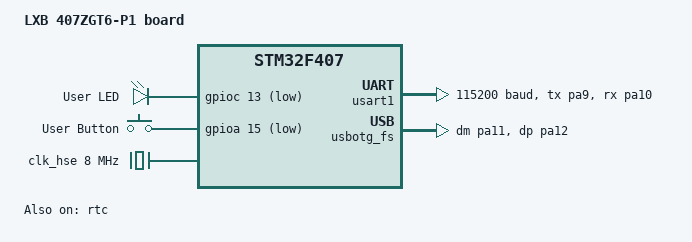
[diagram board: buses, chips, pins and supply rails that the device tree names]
/*
 * Copyright (c) 2026
 *
 * SPDX-License-Identifier: Apache-2.0
 *
 * Device tree for the LXB 407ZGT6-P1 core board (STM32F407ZGT6).
 */

/dts-v1/;
#include <st/f4/stm32f407Xg.dtsi>
#include <st/f4/stm32f407z(e-g)tx-pinctrl.dtsi>
#include <zephyr/dt-bindings/input/input-event-codes.h>

/ {
	model = "LXB 407ZGT6-P1 board";
	compatible = "st,stm32f407";

	chosen {
		zephyr,console = &usart1;
		zephyr,shell-uart = &usart1;
		zephyr,sram = &sram0;
		zephyr,flash = &flash0;
		zephyr,dtcm = &ccm0;
	};

	leds {
		compatible = "gpio-leds";

		user_led: led_0 {
			gpios = <&gpioc 13 GPIO_ACTIVE_LOW>;
			label = "User LED";
		};
	};

	gpio_keys {
		compatible = "gpio-keys";

		user_button: button_0 {
			label = "User Button";
			gpios = <&gpioa 15 (GPIO_ACTIVE_LOW | GPIO_PULL_UP)>;
			zephyr,code = <INPUT_KEY_0>;
		};
	};

	aliases {
		led0 = &user_led;
		sw0 = &user_button;
	};
};

&clk_lsi {
	status = "okay";
};

&clk_hse {
	clock-frequency = <DT_FREQ_M(8)>;
	status = "okay";
};

&pll {
	div-m = <8>;
	mul-n = <336>;
	div-p = <2>;
	div-q = <7>;
	clocks = <&clk_hse>;
	status = "okay";
};

&rcc {
	clocks = <&pll>;
	clock-frequency = <DT_FREQ_M(168)>;
	ahb-prescaler = <1>;
	apb1-prescaler = <4>;
	apb2-prescaler = <2>;
};

&usart1 {
	pinctrl-0 = <&usart1_tx_pa9 &usart1_rx_pa10>;
	pinctrl-names = "default";
	current-speed = <115200>;
	status = "okay";
};

&rtc {
	clocks = <&rcc STM32_CLOCK(APB1, 28)>,
		 <&rcc STM32_SRC_LSI RTC_SEL(2)>;
	status = "okay";
};

zephyr_udc0: &usbotg_fs {
	pinctrl-0 = <&usb_otg_fs_dm_pa11 &usb_otg_fs_dp_pa12>;
	pinctrl-names = "default";
	status = "okay";
};
